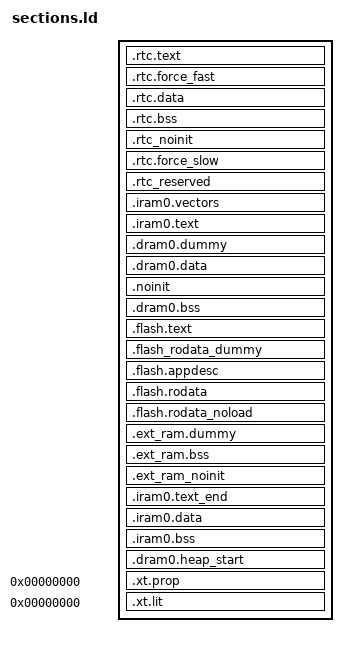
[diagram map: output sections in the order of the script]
/* Automatically generated file; DO NOT EDIT */
/* Espressif IoT Development Framework Linker Script */
/* Generated from: E:\esp\v5.1.6\esp-idf\components\esp_system\ld\esp32s3\sections.ld.in */

/*
 * SPDX-FileCopyrightText: 2021 Espressif Systems (Shanghai) CO LTD
 *
 * SPDX-License-Identifier: Apache-2.0
 */

/* Default entry point */
ENTRY(call_start_cpu0);

_diram_i_start = 0x40378000;

SECTIONS
{
  /**
   * RTC fast memory holds RTC wake stub code,
   * including from any source file named rtc_wake_stub*.c
   */
  .rtc.text :
  {
    . = ALIGN(4);
    _rtc_fast_start = ABSOLUTE(.);
    _rtc_text_start = ABSOLUTE(.);
    *(.rtc.entry.text)

    *(.rtc.literal .rtc.text .rtc.text.*)

    *rtc_wake_stub*.*(.literal .text .literal.* .text.*)
    *(.rtc_text_end_test)

    /* 16B padding for possible CPU prefetch and 4B alignment for PMS split lines */
    . += _esp_memprot_prefetch_pad_size;
    . = ALIGN(4);

    _rtc_text_end = ABSOLUTE(.);
  } > rtc_iram_seg

  /**
   * This section located in RTC FAST Memory area.
   * It holds data marked with RTC_FAST_ATTR attribute.
   * See the file "esp_attr.h" for more information.
   */
  .rtc.force_fast :
  {
    . = ALIGN(4);
    _rtc_force_fast_start = ABSOLUTE(.);

    _coredump_rtc_fast_start = ABSOLUTE(.);
    *(.rtc.fast.coredump .rtc.fast.coredump.*)
    _coredump_rtc_fast_end = ABSOLUTE(.);

    *(.rtc.force_fast .rtc.force_fast.*)
    . = ALIGN(4) ;
    _rtc_force_fast_end = ABSOLUTE(.);
  } > rtc_data_seg

  /**
   * RTC data section holds RTC wake stub
   * data/rodata, including from any source file
   * named rtc_wake_stub*.c and the data marked with
   * RTC_DATA_ATTR, RTC_RODATA_ATTR attributes.
   * The memory location of the data is dependent on
   * CONFIG_ESP32S3_RTCDATA_IN_FAST_MEM option.
   */
  .rtc.data :
  {
    _rtc_data_start = ABSOLUTE(.);

    _coredump_rtc_start = ABSOLUTE(.);
    *(.rtc.coredump .rtc.coredump.*)
    _coredump_rtc_end = ABSOLUTE(.);
    *(.rtc.data .rtc.data.*)
    *(.rtc.rodata .rtc.rodata.*)

    *rtc_wake_stub*.*(.data .rodata .data.* .rodata.*)
    _rtc_data_end = ABSOLUTE(.);
  } > rtc_data_location

  /* RTC bss, from any source file named rtc_wake_stub*.c */
  .rtc.bss (NOLOAD) :
  {
    _rtc_bss_start = ABSOLUTE(.);
    *rtc_wake_stub*.*(.bss .bss.*)
    *rtc_wake_stub*.*(COMMON)

    *(.rtc.bss)

    _rtc_bss_end = ABSOLUTE(.);
  } > rtc_data_location

  /**
   * This section holds data that should not be initialized at power up
   * and will be retained during deep sleep.
   * User data marked with RTC_NOINIT_ATTR will be placed
   * into this section. See the file "esp_attr.h" for more information.
	 * The memory location of the data is dependent on CONFIG_ESP32S3_RTCDATA_IN_FAST_MEM option.
   */
  .rtc_noinit (NOLOAD):
  {
    . = ALIGN(4);
    _rtc_noinit_start = ABSOLUTE(.);
    *(.rtc_noinit .rtc_noinit.*)
    . = ALIGN(4) ;
    _rtc_noinit_end = ABSOLUTE(.);
  } > rtc_data_location

  /**
   * This section located in RTC SLOW Memory area.
   * It holds data marked with RTC_SLOW_ATTR attribute.
   * See the file "esp_attr.h" for more information.
   */
  .rtc.force_slow :
  {
    . = ALIGN(4);
    _rtc_force_slow_start = ABSOLUTE(.);
    *(.rtc.force_slow .rtc.force_slow.*)
    . = ALIGN(4) ;
    _rtc_force_slow_end = ABSOLUTE(.);
  } > rtc_slow_seg

  /**
   * This section holds RTC data that should have fixed addresses.
   * The data are not initialized at power-up and are retained during deep sleep.
   */
  .rtc_reserved (NOLOAD):
  {
    . = ALIGN(4);
    _rtc_reserved_start = ABSOLUTE(.);
    /* New data can only be added here to ensure existing data are not moved.
       Because data have adhered to the end of the segment and code is relied on it.
       >> put new data here << */

    *(.rtc_timer_data_in_rtc_mem .rtc_timer_data_in_rtc_mem.*)
    KEEP(*(.bootloader_data_rtc_mem .bootloader_data_rtc_mem.*))
    _rtc_reserved_end = ABSOLUTE(.);
  } > rtc_reserved_seg

  _rtc_reserved_length = _rtc_reserved_end - _rtc_reserved_start;
  ASSERT((_rtc_reserved_length <= LENGTH(rtc_reserved_seg)),
          "RTC reserved segment data does not fit.")

  /* Get size of rtc slow data based on rtc_data_location alias */
  _rtc_slow_length = (ORIGIN(rtc_slow_seg) == ORIGIN(rtc_data_location))
                        ? (_rtc_force_slow_end - _rtc_data_start)
                        : (_rtc_force_slow_end - _rtc_force_slow_start);

  _rtc_fast_length = (ORIGIN(rtc_slow_seg) == ORIGIN(rtc_data_location))
                        ? (_rtc_force_fast_end - _rtc_fast_start)
                        : (_rtc_noinit_end - _rtc_fast_start);

  ASSERT((_rtc_slow_length <= LENGTH(rtc_slow_seg)),
          "RTC_SLOW segment data does not fit.")

  ASSERT((_rtc_fast_length <= LENGTH(rtc_data_seg)),
          "RTC_FAST segment data does not fit.")

  /* Send .iram0 code to iram */
  .iram0.vectors :
  {
    _iram_start = ABSOLUTE(.);
    /* Vectors go to IRAM */
    _vector_table = ABSOLUTE(.);
    . = 0x0;
    KEEP(*(.WindowVectors.text));
    . = 0x180;
    KEEP(*(.Level2InterruptVector.text));
    . = 0x1c0;
    KEEP(*(.Level3InterruptVector.text));
    . = 0x200;
    KEEP(*(.Level4InterruptVector.text));
    . = 0x240;
    KEEP(*(.Level5InterruptVector.text));
    . = 0x280;
    KEEP(*(.DebugExceptionVector.text));
    . = 0x2c0;
    KEEP(*(.NMIExceptionVector.text));
    . = 0x300;
    KEEP(*(.KernelExceptionVector.text));
    . = 0x340;
    KEEP(*(.UserExceptionVector.text));
    . = 0x3C0;
    KEEP(*(.DoubleExceptionVector.text));
    . = 0x400;
    _invalid_pc_placeholder = ABSOLUTE(.);
    *(.*Vector.literal)

    *(.UserEnter.literal);
    *(.UserEnter.text);
    . = ALIGN (16);
    *(.entry.text)
    *(.init.literal)
    *(.init)
    _init_end = ABSOLUTE(.);
  } > iram0_0_seg

  .iram0.text :
  {
    /* Code marked as running out of IRAM */
    _iram_text_start = ABSOLUTE(.);

    *(.iram1 .iram1.*)
    *libapp_trace.a:app_trace.*(.literal .literal.* .text .text.*)
    *libapp_trace.a:app_trace_util.*(.literal .literal.* .text .text.*)
    *libapp_trace.a:port_uart.*(.literal .literal.* .text .text.*)
    *libdriver.a:gptimer.*(.literal.gptimer_default_isr .text.gptimer_default_isr)
    *libesp_event.a:default_event_loop.*(.literal.esp_event_isr_post .text.esp_event_isr_post)
    *libesp_event.a:esp_event.*(.literal.esp_event_isr_post_to .text.esp_event_isr_post_to)
    *libesp_hw_support.a:cpu.*(.literal.esp_cpu_compare_and_set .text.esp_cpu_compare_and_set)
    *libesp_hw_support.a:cpu.*(.literal.esp_cpu_reset .text.esp_cpu_reset)
    *libesp_hw_support.a:cpu.*(.literal.esp_cpu_stall .text.esp_cpu_stall)
    *libesp_hw_support.a:cpu.*(.literal.esp_cpu_unstall .text.esp_cpu_unstall)
    *libesp_hw_support.a:cpu.*(.literal.esp_cpu_wait_for_intr .text.esp_cpu_wait_for_intr)
    *libesp_hw_support.a:esp_gpio_reserve.*(.literal.esp_gpio_is_pin_reserved .text.esp_gpio_is_pin_reserved)
    *libesp_hw_support.a:esp_gpio_reserve.*(.literal.esp_gpio_reserve_pins .text.esp_gpio_reserve_pins)
    *libesp_hw_support.a:esp_memory_utils.*(.literal .literal.* .text .text.*)
    *libesp_hw_support.a:mspi_timing_config.*(.literal .literal.* .text .text.*)
    *libesp_hw_support.a:mspi_timing_tuning.*(.literal .literal.* .text .text.*)
    *libesp_hw_support.a:rtc_clk.*(.literal .literal.* .text .text.*)
    *libesp_hw_support.a:rtc_sleep.*(.literal .literal.* .text .text.*)
    *libesp_hw_support.a:rtc_time.*(.literal .literal.* .text .text.*)
    *libesp_hw_support.a:sar_periph_ctrl.*(.literal.sar_periph_ctrl_power_enable .text.sar_periph_ctrl_power_enable)
    *libesp_hw_support.a:sleep_console.*(.literal .literal.* .text .text.*)
    *libesp_hw_support.a:systimer.*(.literal .literal.* .text .text.*)
    *libesp_mm.a:esp_cache.*(.literal .literal.* .text .text.*)
    *libesp_psram.a:esp_psram_impl_octal.*(.literal .literal.* .text .text.*)
    *libesp_psram.a:mmu_psram_flash.*(.literal .literal.* .text .text.*)
    *libesp_ringbuf.a:(EXCLUDE_FILE(*libesp_ringbuf.a:ringbuf.*) .literal EXCLUDE_FILE(*libesp_ringbuf.a:ringbuf.*) .literal.* EXCLUDE_FILE(*libesp_ringbuf.a:ringbuf.*) .text EXCLUDE_FILE(*libesp_ringbuf.a:ringbuf.*) .text.*)
    *libesp_ringbuf.a:ringbuf.*(.literal.prvAcquireItemNoSplit .literal.prvCheckItemFitsByteBuffer .literal.prvCheckItemFitsDefault .literal.prvCopyItemAllowSplit .literal.prvCopyItemByteBuf .literal.prvCopyItemNoSplit .literal.prvGetItemByteBuf .literal.prvGetItemDefault .literal.prvReceiveGenericFromISR .literal.prvReturnItemByteBuf .literal.prvReturnItemDefault .literal.prvSendItemDoneNoSplit .literal.vRingbufferReturnItemFromISR .literal.xRingbufferReceiveFromISR .literal.xRingbufferReceiveSplitFromISR .literal.xRingbufferReceiveUpToFromISR .literal.xRingbufferSendFromISR .text .text.prvAcquireItemNoSplit .text.prvCheckItemAvail .text.prvCheckItemFitsByteBuffer .text.prvCheckItemFitsDefault .text.prvCopyItemAllowSplit .text.prvCopyItemByteBuf .text.prvCopyItemNoSplit .text.prvGetItemByteBuf .text.prvGetItemDefault .text.prvReceiveGenericFromISR .text.prvReturnItemByteBuf .text.prvReturnItemDefault .text.prvSendItemDoneNoSplit .text.vRingbufferReturnItemFromISR .text.xRingbufferReceiveFromISR .text.xRingbufferReceiveSplitFromISR .text.xRingbufferReceiveUpToFromISR .text.xRingbufferSendFromISR)
    *libesp_rom.a:esp_rom_cache_esp32s2_esp32s3.*(.literal .literal.* .text .text.*)
    *libesp_rom.a:esp_rom_cache_writeback_esp32s3.*(.literal .literal.* .text .text.*)
    *libesp_rom.a:esp_rom_spiflash.*(.literal .literal.* .text .text.*)
    *libesp_rom.a:esp_rom_systimer.*(.literal .literal.* .text .text.*)
    *libesp_rom.a:esp_rom_wdt.*(.literal .literal.* .text .text.*)
    *libesp_system.a:esp_err.*(.literal .literal.* .text .text.*)
    *libesp_system.a:esp_system_chip.*(.literal.esp_system_abort .text.esp_system_abort)
    *libesp_system.a:ubsan.*(.literal .literal.* .text .text.*)
    *libfreertos.a:(EXCLUDE_FILE(*libfreertos.a:app_startup.* *libfreertos.a:event_groups.* *libfreertos.a:heap_idf.* *libfreertos.a:idf_additions.* *libfreertos.a:list.* *libfreertos.a:port.* *libfreertos.a:port_common.* *libfreertos.a:queue.* *libfreertos.a:stream_buffer.* *libfreertos.a:tasks.* *libfreertos.a:timers.*) .literal EXCLUDE_FILE(*libfreertos.a:app_startup.* *libfreertos.a:event_groups.* *libfreertos.a:heap_idf.* *libfreertos.a:idf_additions.* *libfreertos.a:list.* *libfreertos.a:port.* *libfreertos.a:port_common.* *libfreertos.a:queue.* *libfreertos.a:stream_buffer.* *libfreertos.a:tasks.* *libfreertos.a:timers.*) .literal.* EXCLUDE_FILE(*libfreertos.a:app_startup.* *libfreertos.a:event_groups.* *libfreertos.a:heap_idf.* *libfreertos.a:idf_additions.* *libfreertos.a:list.* *libfreertos.a:port.* *libfreertos.a:port_common.* *libfreertos.a:queue.* *libfreertos.a:stream_buffer.* *libfreertos.a:tasks.* *libfreertos.a:timers.*) .text EXCLUDE_FILE(*libfreertos.a:app_startup.* *libfreertos.a:event_groups.* *libfreertos.a:heap_idf.* *libfreertos.a:idf_additions.* *libfreertos.a:list.* *libfreertos.a:port.* *libfreertos.a:port_common.* *libfreertos.a:queue.* *libfreertos.a:stream_buffer.* *libfreertos.a:tasks.* *libfreertos.a:timers.*) .text.*)
    *libfreertos.a:event_groups.*(.literal.xEventGroupGetBitsFromISR .literal.xEventGroupGetStaticBuffer .text .text.xEventGroupGetBitsFromISR .text.xEventGroupGetStaticBuffer)
    *libfreertos.a:heap_idf.*(.text)
    *libfreertos.a:list.*(.text .text.uxListRemove .text.vListInsert .text.vListInsertEnd)
    *libfreertos.a:port.*(.literal.unlikely.vPortEndScheduler .literal.vApplicationStackOverflowHook .literal.vPortAssertIfInISR .literal.vPortExitCritical .literal.vPortExitCriticalCompliance .literal.vPortSetStackWatchpoint .literal.vPortYieldOtherCore .literal.xPortEnterCriticalTimeout .literal.xPortEnterCriticalTimeoutCompliance .literal.xPortInIsrContext .text .text.unlikely.vPortEndScheduler .text.vApplicationStackOverflowHook .text.vPortAssertIfInISR .text.vPortExitCritical .text.vPortExitCriticalCompliance .text.vPortSetStackWatchpoint .text.vPortYieldOtherCore .text.xPortEnterCriticalTimeout .text.xPortEnterCriticalTimeoutCompliance .text.xPortInIsrContext)
    *libfreertos.a:port_common.*(.text)
    *libfreertos.a:queue.*(.literal.prvCopyDataFromQueue .literal.prvCopyDataToQueue .literal.prvNotifyQueueSetContainer .literal.uxQueueMessagesWaitingFromISR .literal.xQueueGenericGetStaticBuffers .literal.xQueueGenericSendFromISR .literal.xQueueGetMutexHolderFromISR .literal.xQueueGiveFromISR .literal.xQueueIsQueueEmptyFromISR .literal.xQueueIsQueueFullFromISR .literal.xQueuePeekFromISR .literal.xQueueReceiveFromISR .literal.xQueueSelectFromSetFromISR .text .text.prvCopyDataFromQueue .text.prvCopyDataToQueue .text.prvNotifyQueueSetContainer .text.uxQueueMessagesWaitingFromISR .text.xQueueGenericGetStaticBuffers .text.xQueueGenericSendFromISR .text.xQueueGetMutexHolderFromISR .text.xQueueGiveFromISR .text.xQueueIsQueueEmptyFromISR .text.xQueueIsQueueFullFromISR .text.xQueuePeekFromISR .text.xQueueReceiveFromISR .text.xQueueSelectFromSetFromISR)
    *libfreertos.a:stream_buffer.*(.literal.xStreamBufferGetStaticBuffers .literal.xStreamBufferReceiveCompletedFromISR .literal.xStreamBufferReceiveFromISR .literal.xStreamBufferSendCompletedFromISR .literal.xStreamBufferSendFromISR .literal.xStreamBufferSpacesAvailable .text .text.prvBytesInBuffer .text.xStreamBufferGetStaticBuffers .text.xStreamBufferReceiveCompletedFromISR .text.xStreamBufferReceiveFromISR .text.xStreamBufferSendCompletedFromISR .text.xStreamBufferSendFromISR .text.xStreamBufferSpacesAvailable)
    *libfreertos.a:tasks.*(.literal.__getreent .literal.prvCheckForYieldUsingPrioritySMP .literal.prvInitialiseNewTask$constprop$0 .literal.prvResetNextTaskUnblockTime .literal.prvTaskIsTaskSuspended .literal.pxGetNextTaskList .literal.pxTaskGetNext .literal.uxTaskGetSnapshotAll .literal.uxTaskPriorityGetFromISR .literal.vTaskGenericNotifyGiveFromISR .literal.vTaskGetSnapshot .literal.vTaskSwitchContext .literal.xTaskCatchUpTicks .literal.xTaskGenericNotifyFromISR .literal.xTaskGetSchedulerState .literal.xTaskGetStaticBuffers .literal.xTaskGetTickCount .literal.xTaskGetTickCountFromISR .literal.xTaskIncrementTick .literal.xTaskIncrementTickOtherCores .literal.xTaskRemoveFromEventList .literal.xTaskResumeFromISR .text .text.__getreent .text.prvCheckForYieldUsingPrioritySMP .text.prvInitialiseNewTask$constprop$0 .text.prvResetNextTaskUnblockTime .text.prvTaskIsTaskSuspended .text.pxGetNextTaskList .text.pxTaskGetNext .text.uxTaskGetSnapshotAll .text.uxTaskPriorityGetFromISR .text.vTaskGenericNotifyGiveFromISR .text.vTaskGetSnapshot .text.vTaskSwitchContext .text.xTaskCatchUpTicks .text.xTaskGenericNotifyFromISR .text.xTaskGetSchedulerState .text.xTaskGetStaticBuffers .text.xTaskGetTickCount .text.xTaskGetTickCountFromISR .text.xTaskIncrementTick .text.xTaskIncrementTickOtherCores .text.xTaskRemoveFromEventList .text.xTaskResumeFromISR .text.xTimerCreateTimerTask)
    *libfreertos.a:timers.*(.literal.xTimerGetStaticBuffer .literal.xTimerPendFunctionCallFromISR .text .text.xTimerGetStaticBuffer .text.xTimerPendFunctionCallFromISR)
    *libgcc.a:_divsf3.*(.literal .literal.* .text .text.*)
    *libgcc.a:lib2funcs.*(.literal .literal.* .text .text.*)
    *libgcov.a:(.literal .literal.* .text .text.*)
    *libhal.a:cache_hal.*(.literal .literal.* .text .text.*)
    *libhal.a:i2c_hal_iram.*(.literal .literal.* .text .text.*)
    *libhal.a:ledc_hal_iram.*(.literal .literal.* .text .text.*)
    *libhal.a:mmu_hal.*(.literal .literal.* .text .text.*)
    *libhal.a:spi_flash_encrypt_hal_iram.*(.literal .literal.* .text .text.*)
    *libhal.a:spi_flash_hal_gpspi.*(.literal .literal.* .text .text.*)
    *libhal.a:spi_flash_hal_iram.*(.literal .literal.* .text .text.*)
    *libhal.a:systimer_hal.*(.literal .literal.* .text .text.*)
    *libhal.a:timer_hal.*(.literal.timer_hal_capture_and_get_counter_value .text.timer_hal_capture_and_get_counter_value)
    *libheap.a:multi_heap.*(.literal.assert_valid_block .text.assert_valid_block)
    *libheap.a:multi_heap.*(.literal.multi_heap_aligned_alloc_impl .text.multi_heap_aligned_alloc_impl)
    *libheap.a:multi_heap.*(.literal.multi_heap_aligned_alloc_impl_offs .text.multi_heap_aligned_alloc_impl_offs)
    *libheap.a:multi_heap.*(.literal.multi_heap_free_impl .text.multi_heap_free_impl)
    *libheap.a:multi_heap.*(.literal.multi_heap_get_allocated_size_impl .text.multi_heap_get_allocated_size_impl)
    *libheap.a:multi_heap.*(.literal.multi_heap_get_block_address_impl .text.multi_heap_get_block_address_impl)
    *libheap.a:multi_heap.*(.literal.multi_heap_get_first_block .text.multi_heap_get_first_block)
    *libheap.a:multi_heap.*(.literal.multi_heap_get_next_block .text.multi_heap_get_next_block)
    *libheap.a:multi_heap.*(.literal.multi_heap_internal_lock .text.multi_heap_internal_lock)
    *libheap.a:multi_heap.*(.literal.multi_heap_internal_unlock .text.multi_heap_internal_unlock)
    *libheap.a:multi_heap.*(.literal.multi_heap_is_free .text.multi_heap_is_free)
    *libheap.a:multi_heap.*(.literal.multi_heap_malloc_impl .text.multi_heap_malloc_impl)
    *libheap.a:multi_heap.*(.literal.multi_heap_realloc_impl .text.multi_heap_realloc_impl)
    *libheap.a:multi_heap.*(.literal.multi_heap_set_lock .text.multi_heap_set_lock)
    *libheap.a:tlsf.*(.literal.tlsf_align_size .text.tlsf_align_size)
    *libheap.a:tlsf.*(.literal.tlsf_alloc_overhead .text.tlsf_alloc_overhead)
    *libheap.a:tlsf.*(.literal.tlsf_block_size .text.tlsf_block_size)
    *libheap.a:tlsf.*(.literal.tlsf_block_size_max .text.tlsf_block_size_max)
    *libheap.a:tlsf.*(.literal.tlsf_block_size_min .text.tlsf_block_size_min)
    *libheap.a:tlsf.*(.literal.tlsf_free .text.tlsf_free)
    *libheap.a:tlsf.*(.literal.tlsf_get_pool .text.tlsf_get_pool)
    *libheap.a:tlsf.*(.literal.tlsf_malloc .text.tlsf_malloc)
    *libheap.a:tlsf.*(.literal.tlsf_memalign .text.tlsf_memalign)
    *libheap.a:tlsf.*(.literal.tlsf_memalign_offs .text.tlsf_memalign_offs)
    *libheap.a:tlsf.*(.literal.tlsf_realloc .text.tlsf_realloc)
    *libheap.a:tlsf.*(.literal.tlsf_size .text.tlsf_size)
    *liblog.a:log.*(.literal.esp_log_write .text.esp_log_write)
    *liblog.a:log_freertos.*(.literal.esp_log_early_timestamp .text.esp_log_early_timestamp)
    *liblog.a:log_freertos.*(.literal.esp_log_impl_lock .text.esp_log_impl_lock)
    *liblog.a:log_freertos.*(.literal.esp_log_impl_lock_timeout .text.esp_log_impl_lock_timeout)
    *liblog.a:log_freertos.*(.literal.esp_log_impl_unlock .text.esp_log_impl_unlock)
    *liblog.a:log_freertos.*(.literal.esp_log_timestamp .text.esp_log_timestamp)
    *libnewlib.a:abort.*(.literal .literal.* .text .text.*)
    *libnewlib.a:assert.*(.literal .literal.* .text .text.*)
    *libnewlib.a:heap.*(.literal .literal.* .text .text.*)
    *libnewlib.a:stdatomic.*(.literal .literal.* .text .text.*)
    *librtc.a:(.literal .literal.* .text .text.*)
    *libsoc.a:lldesc.*(.literal .literal.* .text .text.*)
    *libspi_flash.a:flash_brownout_hook.*(.literal .literal.* .text .text.*)
    *libspi_flash.a:memspi_host_driver.*(.literal .literal.* .text .text.*)
    *libspi_flash.a:spi_flash_chip_boya.*(.literal .literal.* .text .text.*)
    *libspi_flash.a:spi_flash_chip_gd.*(.literal .literal.* .text .text.*)
    *libspi_flash.a:spi_flash_chip_generic.*(.literal .literal.* .text .text.*)
    *libspi_flash.a:spi_flash_chip_issi.*(.literal .literal.* .text .text.*)
    *libspi_flash.a:spi_flash_chip_mxic.*(.literal .literal.* .text .text.*)
    *libspi_flash.a:spi_flash_chip_mxic_opi.*(.literal .literal.* .text .text.*)
    *libspi_flash.a:spi_flash_chip_th.*(.literal .literal.* .text .text.*)
    *libspi_flash.a:spi_flash_chip_winbond.*(.literal .literal.* .text .text.*)
    *libspi_flash.a:spi_flash_hpm_enable.*(.literal .literal.* .text .text.*)
    *libspi_flash.a:spi_flash_oct_flash_init.*(.literal .literal.* .text .text.*)
    *libspi_flash.a:spi_flash_wrap.*(.literal .literal.* .text .text.*)
    *libxt_hal.a:(.literal .literal.* .text .text.*)
    *libxtensa.a:eri.*(.literal .literal.* .text .text.*)
    *libxtensa.a:xtensa_intr_asm.*(.literal .literal.* .text .text.*)

  } > iram0_0_seg

  /**
   * This section is required to skip .iram0.text area because iram0_0_seg and
   * dram0_0_seg reflect the same address space on different buses.
   */
  .dram0.dummy (NOLOAD):
  {
    . = ORIGIN(dram0_0_seg) + MAX(_iram_end - _diram_i_start, 0);
  } > dram0_0_seg

  .dram0.data :
  {
    _data_start = ABSOLUTE(.);
    *(.gnu.linkonce.d.*)
    *(.data1)
    *(.sdata)
    *(.sdata.*)
    *(.gnu.linkonce.s.*)
    *(.gnu.linkonce.s2.*)
    *(.jcr)

    *(.data .data.*)
    *(.dram1 .dram1.*)
    _coredump_dram_start = ABSOLUTE(.);
    *(.dram2.coredump .dram2.coredump.*)
    _coredump_dram_end = ABSOLUTE(.);
    *libapp_trace.a:app_trace.*(.rodata .rodata.* .sdata2 .sdata2.* .srodata .srodata.*)
    *libapp_trace.a:app_trace_util.*(.rodata .rodata.* .sdata2 .sdata2.* .srodata .srodata.*)
    *libapp_trace.a:port_uart.*(.rodata .rodata.* .sdata2 .sdata2.* .srodata .srodata.*)
    *libesp_hw_support.a:esp_memory_utils.*(.rodata .rodata.* .sdata2 .sdata2.* .srodata .srodata.*)
    *libesp_hw_support.a:mspi_timing_config.*(.rodata .rodata.* .sdata2 .sdata2.* .srodata .srodata.*)
    *libesp_hw_support.a:mspi_timing_tuning.*(.rodata .rodata.* .sdata2 .sdata2.* .srodata .srodata.*)
    *libesp_hw_support.a:rtc_clk.*(.rodata .rodata.* .sdata2 .sdata2.* .srodata .srodata.*)
    *libesp_hw_support.a:sleep_console.*(.rodata .rodata.* .sdata2 .sdata2.* .srodata .srodata.*)
    *libesp_hw_support.a:systimer.*(.rodata .rodata.* .sdata2 .sdata2.* .srodata .srodata.*)
    *libesp_mm.a:esp_cache.*(.rodata .rodata.* .sdata2 .sdata2.* .srodata .srodata.*)
    *libesp_psram.a:esp_psram_impl_octal.*(.rodata .rodata.* .sdata2 .sdata2.* .srodata .srodata.*)
    *libesp_psram.a:mmu_psram_flash.*(.rodata .rodata.* .sdata2 .sdata2.* .srodata .srodata.*)
    *libesp_rom.a:esp_rom_cache_esp32s2_esp32s3.*(.rodata .rodata.* .sdata2 .sdata2.* .srodata .srodata.*)
    *libesp_rom.a:esp_rom_cache_writeback_esp32s3.*(.rodata .rodata.* .sdata2 .sdata2.* .srodata .srodata.*)
    *libesp_rom.a:esp_rom_spiflash.*(.rodata .rodata.* .sdata2 .sdata2.* .srodata .srodata.*)
    *libesp_rom.a:esp_rom_systimer.*(.rodata .rodata.* .sdata2 .sdata2.* .srodata .srodata.*)
    *libesp_rom.a:esp_rom_wdt.*(.rodata .rodata.* .sdata2 .sdata2.* .srodata .srodata.*)
    *libesp_system.a:esp_err.*(.rodata .rodata.* .sdata2 .sdata2.* .srodata .srodata.*)
    *libesp_system.a:ubsan.*(.rodata .rodata.* .sdata2 .sdata2.* .srodata .srodata.*)
    *libfreertos.a:FreeRTOS-openocd.*(.rodata .rodata.* .sdata2 .sdata2.* .srodata .srodata.*)
    *libgcc.a:_divsf3.*(.rodata .rodata.* .sdata2 .sdata2.* .srodata .srodata.*)
    *libgcov.a:(.rodata .rodata.* .sdata2 .sdata2.* .srodata .srodata.*)
    *libhal.a:cache_hal.*(.rodata .rodata.* .sdata2 .sdata2.* .srodata .srodata.*)
    *libhal.a:i2c_hal_iram.*(.rodata .rodata.* .sdata2 .sdata2.* .srodata .srodata.*)
    *libhal.a:ledc_hal_iram.*(.rodata .rodata.* .sdata2 .sdata2.* .srodata .srodata.*)
    *libhal.a:mmu_hal.*(.rodata .rodata.* .sdata2 .sdata2.* .srodata .srodata.*)
    *libhal.a:spi_flash_encrypt_hal_iram.*(.rodata .rodata.* .sdata2 .sdata2.* .srodata .srodata.*)
    *libhal.a:spi_flash_hal_gpspi.*(.rodata .rodata.* .sdata2 .sdata2.* .srodata .srodata.*)
    *libhal.a:spi_flash_hal_iram.*(.rodata .rodata.* .sdata2 .sdata2.* .srodata .srodata.*)
    *libhal.a:systimer_hal.*(.rodata .rodata.* .sdata2 .sdata2.* .srodata .srodata.*)
    *libnewlib.a:abort.*(.rodata .rodata.* .sdata2 .sdata2.* .srodata .srodata.*)
    *libnewlib.a:assert.*(.rodata .rodata.* .sdata2 .sdata2.* .srodata .srodata.*)
    *libnewlib.a:heap.*(.rodata .rodata.* .sdata2 .sdata2.* .srodata .srodata.*)
    *libnewlib.a:stdatomic.*(.rodata .rodata.* .sdata2 .sdata2.* .srodata .srodata.*)
    *libphy.a:(.rodata .rodata.* .sdata2 .sdata2.* .srodata .srodata.*)
    *libsoc.a:lldesc.*(.rodata .rodata.* .sdata2 .sdata2.* .srodata .srodata.*)
    *libspi_flash.a:flash_brownout_hook.*(.rodata .rodata.* .sdata2 .sdata2.* .srodata .srodata.*)
    *libspi_flash.a:memspi_host_driver.*(.rodata .rodata.* .sdata2 .sdata2.* .srodata .srodata.*)
    *libspi_flash.a:spi_flash_chip_boya.*(.rodata .rodata.* .sdata2 .sdata2.* .srodata .srodata.*)
    *libspi_flash.a:spi_flash_chip_gd.*(.rodata .rodata.* .sdata2 .sdata2.* .srodata .srodata.*)
    *libspi_flash.a:spi_flash_chip_generic.*(.rodata .rodata.* .sdata2 .sdata2.* .srodata .srodata.*)
    *libspi_flash.a:spi_flash_chip_issi.*(.rodata .rodata.* .sdata2 .sdata2.* .srodata .srodata.*)
    *libspi_flash.a:spi_flash_chip_mxic.*(.rodata .rodata.* .sdata2 .sdata2.* .srodata .srodata.*)
    *libspi_flash.a:spi_flash_chip_mxic_opi.*(.rodata .rodata.* .sdata2 .sdata2.* .srodata .srodata.*)
    *libspi_flash.a:spi_flash_chip_th.*(.rodata .rodata.* .sdata2 .sdata2.* .srodata .srodata.*)
    *libspi_flash.a:spi_flash_chip_winbond.*(.rodata .rodata.* .sdata2 .sdata2.* .srodata .srodata.*)
    *libspi_flash.a:spi_flash_hpm_enable.*(.rodata .rodata.* .sdata2 .sdata2.* .srodata .srodata.*)
    *libspi_flash.a:spi_flash_oct_flash_init.*(.rodata .rodata.* .sdata2 .sdata2.* .srodata .srodata.*)
    *libspi_flash.a:spi_flash_wrap.*(.rodata .rodata.* .sdata2 .sdata2.* .srodata .srodata.*)

    _data_end = ABSOLUTE(.);
    . = ALIGN(4);
  } > dram0_0_seg

  /**
   * This section holds data that should not be initialized at power up.
   * The section located in Internal SRAM memory region. The macro _NOINIT
   * can be used as attribute to place data into this section.
   * See the "esp_attr.h" file for more information.
   */
  .noinit (NOLOAD):
  {
    . = ALIGN(4);
    _noinit_start = ABSOLUTE(.);
    *(.noinit .noinit.*)
    . = ALIGN(4) ;
    _noinit_end = ABSOLUTE(.);
  } > dram0_0_seg

  /* Shared RAM */
  .dram0.bss (NOLOAD) :
  {
    . = ALIGN (8);
    _bss_start = ABSOLUTE(.);

    *(.bss .bss.*)
    *(.dynbss .dynsbss .gnu.linkonce.b .gnu.linkonce.b.* .gnu.linkonce.sb .gnu.linkonce.sb.* .gnu.linkonce.sb2 .gnu.linkonce.sb2.* .sbss .sbss.* .sbss2 .sbss2.* .scommon .share.mem)
    *(.ext_ram.bss .ext_ram.bss.*)
    *(COMMON)

    *(.dynsbss)
    *(.sbss)
    *(.sbss.*)
    *(.gnu.linkonce.sb.*)
    *(.scommon)
    *(.sbss2)
    *(.sbss2.*)
    *(.gnu.linkonce.sb2.*)
    *(.dynbss)
    *(.share.mem)
    *(.gnu.linkonce.b.*)

    . = ALIGN (8);
    _bss_end = ABSOLUTE(.);
  } > dram0_0_seg

  ASSERT(((_bss_end - ORIGIN(dram0_0_seg)) <= LENGTH(dram0_0_seg)), "DRAM segment data does not fit.")

  .flash.text :
  {
    _stext = .;
    _instruction_reserved_start = ABSOLUTE(.);  /* This is a symbol marking the flash.text start, this can be used for mmu driver to maintain virtual address */
    _text_start = ABSOLUTE(.);

    *(EXCLUDE_FILE(*libesp_ringbuf.a *libfreertos.a *libgcov.a *librtc.a *libxt_hal.a *libapp_trace.a:app_trace.* *libapp_trace.a:app_trace_util.* *libapp_trace.a:port_uart.* *libdriver.a:gptimer.* *libesp_event.a:default_event_loop.* *libesp_event.a:esp_event.* *libesp_hw_support.a:cpu.* *libesp_hw_support.a:esp_gpio_reserve.* *libesp_hw_support.a:esp_memory_utils.* *libesp_hw_support.a:mspi_timing_config.* *libesp_hw_support.a:mspi_timing_tuning.* *libesp_hw_support.a:rtc_clk.* *libesp_hw_support.a:rtc_sleep.* *libesp_hw_support.a:rtc_time.* *libesp_hw_support.a:sar_periph_ctrl.* *libesp_hw_support.a:sleep_console.* *libesp_hw_support.a:systimer.* *libesp_mm.a:esp_cache.* *libesp_psram.a:esp_psram_impl_octal.* *libesp_psram.a:mmu_psram_flash.* *libesp_rom.a:esp_rom_cache_esp32s2_esp32s3.* *libesp_rom.a:esp_rom_cache_writeback_esp32s3.* *libesp_rom.a:esp_rom_spiflash.* *libesp_rom.a:esp_rom_systimer.* *libesp_rom.a:esp_rom_wdt.* *libesp_system.a:esp_err.* *libesp_system.a:esp_system_chip.* *libesp_system.a:ubsan.* *libgcc.a:_divsf3.* *libgcc.a:lib2funcs.* *libhal.a:cache_hal.* *libhal.a:i2c_hal_iram.* *libhal.a:ledc_hal_iram.* *libhal.a:mmu_hal.* *libhal.a:spi_flash_encrypt_hal_iram.* *libhal.a:spi_flash_hal_gpspi.* *libhal.a:spi_flash_hal_iram.* *libhal.a:systimer_hal.* *libhal.a:timer_hal.* *libheap.a:multi_heap.* *libheap.a:tlsf.* *liblog.a:log.* *liblog.a:log_freertos.* *libnewlib.a:abort.* *libnewlib.a:assert.* *libnewlib.a:heap.* *libnewlib.a:stdatomic.* *libsoc.a:lldesc.* *libspi_flash.a:flash_brownout_hook.* *libspi_flash.a:memspi_host_driver.* *libspi_flash.a:spi_flash_chip_boya.* *libspi_flash.a:spi_flash_chip_gd.* *libspi_flash.a:spi_flash_chip_generic.* *libspi_flash.a:spi_flash_chip_issi.* *libspi_flash.a:spi_flash_chip_mxic.* *libspi_flash.a:spi_flash_chip_mxic_opi.* *libspi_flash.a:spi_flash_chip_th.* *libspi_flash.a:spi_flash_chip_winbond.* *libspi_flash.a:spi_flash_hpm_enable.* *libspi_flash.a:spi_flash_oct_flash_init.* *libspi_flash.a:spi_flash_wrap.* *libxtensa.a:eri.* *libxtensa.a:xtensa_intr_asm.*) .literal EXCLUDE_FILE(*libesp_ringbuf.a *libfreertos.a *libgcov.a *librtc.a *libxt_hal.a *libapp_trace.a:app_trace.* *libapp_trace.a:app_trace_util.* *libapp_trace.a:port_uart.* *libdriver.a:gptimer.* *libesp_event.a:default_event_loop.* *libesp_event.a:esp_event.* *libesp_hw_support.a:cpu.* *libesp_hw_support.a:esp_gpio_reserve.* *libesp_hw_support.a:esp_memory_utils.* *libesp_hw_support.a:mspi_timing_config.* *libesp_hw_support.a:mspi_timing_tuning.* *libesp_hw_support.a:rtc_clk.* *libesp_hw_support.a:rtc_sleep.* *libesp_hw_support.a:rtc_time.* *libesp_hw_support.a:sar_periph_ctrl.* *libesp_hw_support.a:sleep_console.* *libesp_hw_support.a:systimer.* *libesp_mm.a:esp_cache.* *libesp_psram.a:esp_psram_impl_octal.* *libesp_psram.a:mmu_psram_flash.* *libesp_rom.a:esp_rom_cache_esp32s2_esp32s3.* *libesp_rom.a:esp_rom_cache_writeback_esp32s3.* *libesp_rom.a:esp_rom_spiflash.* *libesp_rom.a:esp_rom_systimer.* *libesp_rom.a:esp_rom_wdt.* *libesp_system.a:esp_err.* *libesp_system.a:esp_system_chip.* *libesp_system.a:ubsan.* *libgcc.a:_divsf3.* *libgcc.a:lib2funcs.* *libhal.a:cache_hal.* *libhal.a:i2c_hal_iram.* *libhal.a:ledc_hal_iram.* *libhal.a:mmu_hal.* *libhal.a:spi_flash_encrypt_hal_iram.* *libhal.a:spi_flash_hal_gpspi.* *libhal.a:spi_flash_hal_iram.* *libhal.a:systimer_hal.* *libhal.a:timer_hal.* *libheap.a:multi_heap.* *libheap.a:tlsf.* *liblog.a:log.* *liblog.a:log_freertos.* *libnewlib.a:abort.* *libnewlib.a:assert.* *libnewlib.a:heap.* *libnewlib.a:stdatomic.* *libsoc.a:lldesc.* *libspi_flash.a:flash_brownout_hook.* *libspi_flash.a:memspi_host_driver.* *libspi_flash.a:spi_flash_chip_boya.* *libspi_flash.a:spi_flash_chip_gd.* *libspi_flash.a:spi_flash_chip_generic.* *libspi_flash.a:spi_flash_chip_issi.* *libspi_flash.a:spi_flash_chip_mxic.* *libspi_flash.a:spi_flash_chip_mxic_opi.* *libspi_flash.a:spi_flash_chip_th.* *libspi_flash.a:spi_flash_chip_winbond.* *libspi_flash.a:spi_flash_hpm_enable.* *libspi_flash.a:spi_flash_oct_flash_init.* *libspi_flash.a:spi_flash_wrap.* *libxtensa.a:eri.* *libxtensa.a:xtensa_intr_asm.*) .literal.* EXCLUDE_FILE(*libesp_ringbuf.a *libfreertos.a *libgcov.a *librtc.a *libxt_hal.a *libapp_trace.a:app_trace.* *libapp_trace.a:app_trace_util.* *libapp_trace.a:port_uart.* *libdriver.a:gptimer.* *libesp_event.a:default_event_loop.* *libesp_event.a:esp_event.* *libesp_hw_support.a:cpu.* *libesp_hw_support.a:esp_gpio_reserve.* *libesp_hw_support.a:esp_memory_utils.* *libesp_hw_support.a:mspi_timing_config.* *libesp_hw_support.a:mspi_timing_tuning.* *libesp_hw_support.a:rtc_clk.* *libesp_hw_support.a:rtc_sleep.* *libesp_hw_support.a:rtc_time.* *libesp_hw_support.a:sar_periph_ctrl.* *libesp_hw_support.a:sleep_console.* *libesp_hw_support.a:systimer.* *libesp_mm.a:esp_cache.* *libesp_psram.a:esp_psram_impl_octal.* *libesp_psram.a:mmu_psram_flash.* *libesp_rom.a:esp_rom_cache_esp32s2_esp32s3.* *libesp_rom.a:esp_rom_cache_writeback_esp32s3.* *libesp_rom.a:esp_rom_spiflash.* *libesp_rom.a:esp_rom_systimer.* *libesp_rom.a:esp_rom_wdt.* *libesp_system.a:esp_err.* *libesp_system.a:esp_system_chip.* *libesp_system.a:ubsan.* *libgcc.a:_divsf3.* *libgcc.a:lib2funcs.* *libhal.a:cache_hal.* *libhal.a:i2c_hal_iram.* *libhal.a:ledc_hal_iram.* *libhal.a:mmu_hal.* *libhal.a:spi_flash_encrypt_hal_iram.* *libhal.a:spi_flash_hal_gpspi.* *libhal.a:spi_flash_hal_iram.* *libhal.a:systimer_hal.* *libhal.a:timer_hal.* *libheap.a:multi_heap.* *libheap.a:tlsf.* *liblog.a:log.* *liblog.a:log_freertos.* *libnewlib.a:abort.* *libnewlib.a:assert.* *libnewlib.a:heap.* *libnewlib.a:stdatomic.* *libsoc.a:lldesc.* *libspi_flash.a:flash_brownout_hook.* *libspi_flash.a:memspi_host_driver.* *libspi_flash.a:spi_flash_chip_boya.* *libspi_flash.a:spi_flash_chip_gd.* *libspi_flash.a:spi_flash_chip_generic.* *libspi_flash.a:spi_flash_chip_issi.* *libspi_flash.a:spi_flash_chip_mxic.* *libspi_flash.a:spi_flash_chip_mxic_opi.* *libspi_flash.a:spi_flash_chip_th.* *libspi_flash.a:spi_flash_chip_winbond.* *libspi_flash.a:spi_flash_hpm_enable.* *libspi_flash.a:spi_flash_oct_flash_init.* *libspi_flash.a:spi_flash_wrap.* *libxtensa.a:eri.* *libxtensa.a:xtensa_intr_asm.*) .text EXCLUDE_FILE(*libesp_ringbuf.a *libfreertos.a *libgcov.a *librtc.a *libxt_hal.a *libapp_trace.a:app_trace.* *libapp_trace.a:app_trace_util.* *libapp_trace.a:port_uart.* *libdriver.a:gptimer.* *libesp_event.a:default_event_loop.* *libesp_event.a:esp_event.* *libesp_hw_support.a:cpu.* *libesp_hw_support.a:esp_gpio_reserve.* *libesp_hw_support.a:esp_memory_utils.* *libesp_hw_support.a:mspi_timing_config.* *libesp_hw_support.a:mspi_timing_tuning.* *libesp_hw_support.a:rtc_clk.* *libesp_hw_support.a:rtc_sleep.* *libesp_hw_support.a:rtc_time.* *libesp_hw_support.a:sar_periph_ctrl.* *libesp_hw_support.a:sleep_console.* *libesp_hw_support.a:systimer.* *libesp_mm.a:esp_cache.* *libesp_psram.a:esp_psram_impl_octal.* *libesp_psram.a:mmu_psram_flash.* *libesp_rom.a:esp_rom_cache_esp32s2_esp32s3.* *libesp_rom.a:esp_rom_cache_writeback_esp32s3.* *libesp_rom.a:esp_rom_spiflash.* *libesp_rom.a:esp_rom_systimer.* *libesp_rom.a:esp_rom_wdt.* *libesp_system.a:esp_err.* *libesp_system.a:esp_system_chip.* *libesp_system.a:ubsan.* *libgcc.a:_divsf3.* *libgcc.a:lib2funcs.* *libhal.a:cache_hal.* *libhal.a:i2c_hal_iram.* *libhal.a:ledc_hal_iram.* *libhal.a:mmu_hal.* *libhal.a:spi_flash_encrypt_hal_iram.* *libhal.a:spi_flash_hal_gpspi.* *libhal.a:spi_flash_hal_iram.* *libhal.a:systimer_hal.* *libhal.a:timer_hal.* *libheap.a:multi_heap.* *libheap.a:tlsf.* *liblog.a:log.* *liblog.a:log_freertos.* *libnewlib.a:abort.* *libnewlib.a:assert.* *libnewlib.a:heap.* *libnewlib.a:stdatomic.* *libsoc.a:lldesc.* *libspi_flash.a:flash_brownout_hook.* *libspi_flash.a:memspi_host_driver.* *libspi_flash.a:spi_flash_chip_boya.* *libspi_flash.a:spi_flash_chip_gd.* *libspi_flash.a:spi_flash_chip_generic.* *libspi_flash.a:spi_flash_chip_issi.* *libspi_flash.a:spi_flash_chip_mxic.* *libspi_flash.a:spi_flash_chip_mxic_opi.* *libspi_flash.a:spi_flash_chip_th.* *libspi_flash.a:spi_flash_chip_winbond.* *libspi_flash.a:spi_flash_hpm_enable.* *libspi_flash.a:spi_flash_oct_flash_init.* *libspi_flash.a:spi_flash_wrap.* *libxtensa.a:eri.* *libxtensa.a:xtensa_intr_asm.*) .text.*)
    *(.wifi0iram .wifi0iram.*)
    *(.wifiextrairam .wifiextrairam.*)
    *(.wifiorslpiram .wifiorslpiram.*)
    *(.wifirxiram .wifirxiram.*)
    *(.wifislpiram .wifislpiram.*)
    *(.wifislprxiram .wifislprxiram.*)
    *libdriver.a:gptimer.*(.literal.gptimer_del_timer .literal.gptimer_destroy .literal.gptimer_disable .literal.gptimer_enable .literal.gptimer_get_captured_count .literal.gptimer_get_raw_count .literal.gptimer_get_resolution .literal.gptimer_new_timer .literal.gptimer_register_event_callbacks .literal.gptimer_release_group_handle .literal.gptimer_set_alarm_action .literal.gptimer_set_raw_count .literal.gptimer_start .literal.gptimer_stop .text .text.gptimer_del_timer .text.gptimer_destroy .text.gptimer_disable .text.gptimer_enable .text.gptimer_get_captured_count .text.gptimer_get_raw_count .text.gptimer_get_resolution .text.gptimer_new_timer .text.gptimer_register_event_callbacks .text.gptimer_release_group_handle .text.gptimer_set_alarm_action .text.gptimer_set_raw_count .text.gptimer_start .text.gptimer_stop)
    *libesp_event.a:default_event_loop.*(.literal.esp_event_handler_instance_register .literal.esp_event_handler_instance_unregister .literal.esp_event_handler_register .literal.esp_event_handler_unregister .literal.esp_event_loop_create_default .literal.esp_event_loop_delete_default .literal.esp_event_post .text .text.esp_event_handler_instance_register .text.esp_event_handler_instance_unregister .text.esp_event_handler_register .text.esp_event_handler_unregister .text.esp_event_loop_create_default .text.esp_event_loop_delete_default .text.esp_event_post)
    *libesp_event.a:esp_event.*(.literal.base_node_add_handler .literal.esp_event_handler_instance_register_with .literal.esp_event_handler_instance_unregister_with .literal.esp_event_handler_register_with .literal.esp_event_handler_register_with_internal .literal.esp_event_handler_unregister_with .literal.esp_event_handler_unregister_with_internal .literal.esp_event_loop_create .literal.esp_event_loop_delete .literal.esp_event_loop_run .literal.esp_event_loop_run_task .literal.esp_event_post_to .literal.handler_instances_add .literal.handler_instances_remove .literal.handler_instances_remove_all .literal.loop_node_add_handler .text .text.base_node_add_handler .text.esp_event_dump .text.esp_event_handler_instance_register_with .text.esp_event_handler_instance_unregister_with .text.esp_event_handler_register_with .text.esp_event_handler_register_with_internal .text.esp_event_handler_unregister_with .text.esp_event_handler_unregister_with_internal .text.esp_event_loop_create .text.esp_event_loop_delete .text.esp_event_loop_run .text.esp_event_loop_run_task .text.esp_event_post_to .text.handler_instances_add .text.handler_instances_remove .text.handler_instances_remove_all .text.loop_node_add_handler)
    *libesp_hw_support.a:cpu.*(.literal.esp_cpu_set_watchpoint .text .text.esp_cpu_clear_breakpoint .text.esp_cpu_clear_watchpoint .text.esp_cpu_set_breakpoint .text.esp_cpu_set_watchpoint)
    *libesp_hw_support.a:esp_gpio_reserve.*(.text)
    *libesp_hw_support.a:sar_periph_ctrl.*(.literal.s_sar_power_acquire .literal.s_sar_power_release .literal.sar_periph_ctrl_adc_continuous_power_acquire .literal.sar_periph_ctrl_adc_continuous_power_release .literal.sar_periph_ctrl_adc_oneshot_power_acquire .literal.sar_periph_ctrl_adc_oneshot_power_release .literal.sar_periph_ctrl_init .literal.sar_periph_ctrl_power_disable .literal.sar_periph_ctrl_pwdet_power_acquire .literal.sar_periph_ctrl_pwdet_power_release .text .text.s_sar_power_acquire .text.s_sar_power_release .text.sar_periph_ctrl_adc_continuous_power_acquire .text.sar_periph_ctrl_adc_continuous_power_release .text.sar_periph_ctrl_adc_oneshot_power_acquire .text.sar_periph_ctrl_adc_oneshot_power_release .text.sar_periph_ctrl_init .text.sar_periph_ctrl_power_disable .text.sar_periph_ctrl_pwdet_power_acquire .text.sar_periph_ctrl_pwdet_power_release)
    *libesp_ringbuf.a:ringbuf.*(.literal.prvGetCurMaxSizeAllowSplit .text.prvGetCurMaxSizeAllowSplit)
    *libesp_ringbuf.a:ringbuf.*(.literal.prvGetCurMaxSizeByteBuf .text.prvGetCurMaxSizeByteBuf)
    *libesp_ringbuf.a:ringbuf.*(.literal.prvGetCurMaxSizeNoSplit .text.prvGetCurMaxSizeNoSplit)
    *libesp_ringbuf.a:ringbuf.*(.literal.prvInitializeNewRingbuffer .text.prvInitializeNewRingbuffer)
    *libesp_ringbuf.a:ringbuf.*(.literal.prvReceiveGeneric .text.prvReceiveGeneric)
    *libesp_ringbuf.a:ringbuf.*(.literal.prvSendAcquireGeneric .text.prvSendAcquireGeneric)
    *libesp_ringbuf.a:ringbuf.*(.literal.vRingbufferDelete .text.vRingbufferDelete)
    *libesp_ringbuf.a:ringbuf.*(.literal.vRingbufferGetInfo .text.vRingbufferGetInfo)
    *libesp_ringbuf.a:ringbuf.*(.literal.vRingbufferReturnItem .text.vRingbufferReturnItem)
    *libesp_ringbuf.a:ringbuf.*(.literal.xRingbufferAddToQueueSetRead .text.xRingbufferAddToQueueSetRead)
    *libesp_ringbuf.a:ringbuf.*(.literal.xRingbufferCreate .text.xRingbufferCreate)
    *libesp_ringbuf.a:ringbuf.*(.literal.xRingbufferCreateNoSplit .text.xRingbufferCreateNoSplit)
    *libesp_ringbuf.a:ringbuf.*(.literal.xRingbufferCreateStatic .text.xRingbufferCreateStatic)
    *libesp_ringbuf.a:ringbuf.*(.literal.xRingbufferGetCurFreeSize .text.xRingbufferGetCurFreeSize)
    *libesp_ringbuf.a:ringbuf.*(.literal.xRingbufferGetMaxItemSize .text.xRingbufferGetMaxItemSize)
    *libesp_ringbuf.a:ringbuf.*(.literal.xRingbufferPrintInfo .text.xRingbufferPrintInfo)
    *libesp_ringbuf.a:ringbuf.*(.literal.xRingbufferReceive .text.xRingbufferReceive)
    *libesp_ringbuf.a:ringbuf.*(.literal.xRingbufferReceiveSplit .text.xRingbufferReceiveSplit)
    *libesp_ringbuf.a:ringbuf.*(.literal.xRingbufferReceiveUpTo .text.xRingbufferReceiveUpTo)
    *libesp_ringbuf.a:ringbuf.*(.literal.xRingbufferRemoveFromQueueSetRead .text.xRingbufferRemoveFromQueueSetRead)
    *libesp_ringbuf.a:ringbuf.*(.literal.xRingbufferSend .text.xRingbufferSend)
    *libesp_ringbuf.a:ringbuf.*(.literal.xRingbufferSendAcquire .text.xRingbufferSendAcquire)
    *libesp_ringbuf.a:ringbuf.*(.literal.xRingbufferSendComplete .text.xRingbufferSendComplete)
    *libesp_system.a:esp_system_chip.*(.literal.esp_get_free_heap_size .literal.esp_get_free_internal_heap_size .literal.esp_get_idf_version .literal.esp_get_minimum_free_heap_size .text .text.esp_get_free_heap_size .text.esp_get_free_internal_heap_size .text.esp_get_idf_version .text.esp_get_minimum_free_heap_size)
    *libfreertos.a:app_startup.*(.literal .literal.* .text .text.*)
    *libfreertos.a:event_groups.*(.literal.vEventGroupClearBitsCallback .text.vEventGroupClearBitsCallback)
    *libfreertos.a:event_groups.*(.literal.vEventGroupDelete .text.vEventGroupDelete)
    *libfreertos.a:event_groups.*(.literal.vEventGroupSetBitsCallback .text.vEventGroupSetBitsCallback)
    *libfreertos.a:event_groups.*(.literal.xEventGroupClearBits .text.xEventGroupClearBits)
    *libfreertos.a:event_groups.*(.literal.xEventGroupCreate .text.xEventGroupCreate)
    *libfreertos.a:event_groups.*(.literal.xEventGroupCreateStatic .text.xEventGroupCreateStatic)
    *libfreertos.a:event_groups.*(.literal.xEventGroupSetBits .text.xEventGroupSetBits)
    *libfreertos.a:event_groups.*(.literal.xEventGroupSync .text.xEventGroupSync)
    *libfreertos.a:event_groups.*(.literal.xEventGroupWaitBits .text.xEventGroupWaitBits)
    *libfreertos.a:heap_idf.*(.literal.pvPortMalloc .text.pvPortMalloc)
    *libfreertos.a:heap_idf.*(.literal.vPortFree .text.vPortFree)
    *libfreertos.a:heap_idf.*(.literal.xPortCheckValidTCBMem .text.xPortCheckValidTCBMem)
    *libfreertos.a:heap_idf.*(.literal.xPortGetFreeHeapSize .text.xPortGetFreeHeapSize)
    *libfreertos.a:heap_idf.*(.literal.xPortGetMinimumEverFreeHeapSize .text.xPortGetMinimumEverFreeHeapSize)
    *libfreertos.a:heap_idf.*(.literal.xPortcheckValidStackMem .text.xPortcheckValidStackMem)
    *libfreertos.a:idf_additions.*(.literal .literal.* .text .text.*)
    *libfreertos.a:list.*(.literal.vListInitialise .text.vListInitialise)
    *libfreertos.a:list.*(.literal.vListInitialiseItem .text.vListInitialiseItem)
    *libfreertos.a:port.*(.literal.pxPortInitialiseStack .text.pxPortInitialiseStack)
    *libfreertos.a:port.*(.literal.vPortCleanUpCoprocArea .text.vPortCleanUpCoprocArea)
    *libfreertos.a:port.*(.literal.xPortGetTickRateHz .text.xPortGetTickRateHz)
    *libfreertos.a:port.*(.literal.xPortStartScheduler .text.xPortStartScheduler)
    *libfreertos.a:port_common.*(.literal.vApplicationGetIdleTaskMemory .text.vApplicationGetIdleTaskMemory)
    *libfreertos.a:port_common.*(.literal.vApplicationGetTimerTaskMemory .text.vApplicationGetTimerTaskMemory)
    *libfreertos.a:queue.*(.literal.prvInitialiseMutex .text.prvInitialiseMutex)
    *libfreertos.a:queue.*(.literal.uxQueueMessagesWaiting .text.uxQueueMessagesWaiting)
    *libfreertos.a:queue.*(.literal.uxQueueSpacesAvailable .text.uxQueueSpacesAvailable)
    *libfreertos.a:queue.*(.literal.vQueueDelete .text.vQueueDelete)
    *libfreertos.a:queue.*(.literal.vQueueWaitForMessageRestricted .text.vQueueWaitForMessageRestricted)
    *libfreertos.a:queue.*(.literal.xQueueAddToSet .text.xQueueAddToSet)
    *libfreertos.a:queue.*(.literal.xQueueCreateCountingSemaphore .text.xQueueCreateCountingSemaphore)
    *libfreertos.a:queue.*(.literal.xQueueCreateCountingSemaphoreStatic .text.xQueueCreateCountingSemaphoreStatic)
    *libfreertos.a:queue.*(.literal.xQueueCreateMutex .text.xQueueCreateMutex)
    *libfreertos.a:queue.*(.literal.xQueueCreateMutexStatic .text.xQueueCreateMutexStatic)
    *libfreertos.a:queue.*(.literal.xQueueCreateSet .text.xQueueCreateSet)
    *libfreertos.a:queue.*(.literal.xQueueGenericCreate .text.xQueueGenericCreate)
    *libfreertos.a:queue.*(.literal.xQueueGenericCreateStatic .text.xQueueGenericCreateStatic)
    *libfreertos.a:queue.*(.literal.xQueueGenericReset .text.xQueueGenericReset)
    *libfreertos.a:queue.*(.literal.xQueueGenericSend .text.xQueueGenericSend)
    *libfreertos.a:queue.*(.literal.xQueueGetMutexHolder .text.xQueueGetMutexHolder)
    *libfreertos.a:queue.*(.literal.xQueueGiveMutexRecursive .text.xQueueGiveMutexRecursive)
    *libfreertos.a:queue.*(.literal.xQueuePeek .text.xQueuePeek)
    *libfreertos.a:queue.*(.literal.xQueueReceive .text.xQueueReceive)
    *libfreertos.a:queue.*(.literal.xQueueRemoveFromSet .text.xQueueRemoveFromSet)
    *libfreertos.a:queue.*(.literal.xQueueSelectFromSet .text.xQueueSelectFromSet)
    *libfreertos.a:queue.*(.literal.xQueueSemaphoreTake .text.xQueueSemaphoreTake)
    *libfreertos.a:queue.*(.literal.xQueueTakeMutexRecursive .text.xQueueTakeMutexRecursive)
    *libfreertos.a:stream_buffer.*(.literal.prvInitialiseNewStreamBuffer .text.prvInitialiseNewStreamBuffer)
    *libfreertos.a:stream_buffer.*(.literal.prvReadBytesFromBuffer .text.prvReadBytesFromBuffer)
    *libfreertos.a:stream_buffer.*(.literal.prvWriteBytesToBuffer .text.prvWriteBytesToBuffer)
    *libfreertos.a:stream_buffer.*(.literal.vStreamBufferDelete .text.vStreamBufferDelete)
    *libfreertos.a:stream_buffer.*(.literal.xStreamBufferBytesAvailable .text.xStreamBufferBytesAvailable)
    *libfreertos.a:stream_buffer.*(.literal.xStreamBufferGenericCreate .text.xStreamBufferGenericCreate)
    *libfreertos.a:stream_buffer.*(.literal.xStreamBufferGenericCreateStatic .text.xStreamBufferGenericCreateStatic)
    *libfreertos.a:stream_buffer.*(.literal.xStreamBufferIsEmpty .text.xStreamBufferIsEmpty)
    *libfreertos.a:stream_buffer.*(.literal.xStreamBufferIsFull .text.xStreamBufferIsFull)
    *libfreertos.a:stream_buffer.*(.literal.xStreamBufferNextMessageLengthBytes .text.xStreamBufferNextMessageLengthBytes)
    *libfreertos.a:stream_buffer.*(.literal.xStreamBufferReceive .text.xStreamBufferReceive)
    *libfreertos.a:stream_buffer.*(.literal.xStreamBufferReset .text.xStreamBufferReset)
    *libfreertos.a:stream_buffer.*(.literal.xStreamBufferSend .text.xStreamBufferSend)
    *libfreertos.a:stream_buffer.*(.literal.xStreamBufferSetTriggerLevel .text.xStreamBufferSetTriggerLevel)
    *libfreertos.a:tasks.*(.literal.eTaskGetState .text.eTaskGetState)
    *libfreertos.a:tasks.*(.literal.pcTaskGetName .text.pcTaskGetName)
    *libfreertos.a:tasks.*(.literal.prvAddCurrentTaskToDelayedList .text.prvAddCurrentTaskToDelayedList)
    *libfreertos.a:tasks.*(.literal.prvAddNewTaskToReadyList .text.prvAddNewTaskToReadyList)
    *libfreertos.a:tasks.*(.literal.prvDeleteTCB .text.prvDeleteTCB)
    *libfreertos.a:tasks.*(.literal.prvDeleteTLS .text.prvDeleteTLS)
    *libfreertos.a:tasks.*(.literal.prvIdleTask .text.prvIdleTask)
    *libfreertos.a:tasks.*(.literal.prvSearchForNameWithinSingleList .text.prvSearchForNameWithinSingleList)
    *libfreertos.a:tasks.*(.literal.prvTaskPriorityRaise .text.prvTaskPriorityRaise)
    *libfreertos.a:tasks.*(.literal.prvTaskPriorityRestore .text.prvTaskPriorityRestore)
    *libfreertos.a:tasks.*(.literal.pvTaskGetThreadLocalStoragePointer .text.pvTaskGetThreadLocalStoragePointer)
    *libfreertos.a:tasks.*(.literal.pvTaskIncrementMutexHeldCount .text.pvTaskIncrementMutexHeldCount)
    *libfreertos.a:tasks.*(.literal.pxTaskGetStackStart .text.pxTaskGetStackStart)
    *libfreertos.a:tasks.*(.literal.ulTaskGenericNotifyTake .text.ulTaskGenericNotifyTake)
    *libfreertos.a:tasks.*(.literal.ulTaskGenericNotifyValueClear .text.ulTaskGenericNotifyValueClear)
    *libfreertos.a:tasks.*(.literal.ulTaskNotifyTake .text.ulTaskNotifyTake)
    *libfreertos.a:tasks.*(.literal.uxTaskGetNumberOfTasks .text.uxTaskGetNumberOfTasks)
    *libfreertos.a:tasks.*(.literal.uxTaskGetStackHighWaterMark .text.uxTaskGetStackHighWaterMark)
    *libfreertos.a:tasks.*(.literal.uxTaskGetStackHighWaterMark2 .text.uxTaskGetStackHighWaterMark2)
    *libfreertos.a:tasks.*(.literal.uxTaskPriorityGet .text.uxTaskPriorityGet)
    *libfreertos.a:tasks.*(.literal.uxTaskResetEventItemValue .text.uxTaskResetEventItemValue)
    *libfreertos.a:tasks.*(.literal.vTaskDelay .text.vTaskDelay)
    *libfreertos.a:tasks.*(.literal.vTaskDelayUntil .text.vTaskDelayUntil)
    *libfreertos.a:tasks.*(.literal.vTaskDelete .text.vTaskDelete)
    *libfreertos.a:tasks.*(.literal.vTaskEndScheduler .text.vTaskEndScheduler)
    *libfreertos.a:tasks.*(.literal.vTaskInternalSetTimeOutState .text.vTaskInternalSetTimeOutState)
    *libfreertos.a:tasks.*(.literal.vTaskMissedYield .text.vTaskMissedYield)
    *libfreertos.a:tasks.*(.literal.vTaskPlaceOnEventList .text.vTaskPlaceOnEventList)
    *libfreertos.a:tasks.*(.literal.vTaskPlaceOnEventListRestricted .text.vTaskPlaceOnEventListRestricted)
    *libfreertos.a:tasks.*(.literal.vTaskPlaceOnUnorderedEventList .text.vTaskPlaceOnUnorderedEventList)
    *libfreertos.a:tasks.*(.literal.vTaskPriorityDisinheritAfterTimeout .text.vTaskPriorityDisinheritAfterTimeout)
    *libfreertos.a:tasks.*(.literal.vTaskPrioritySet .text.vTaskPrioritySet)
    *libfreertos.a:tasks.*(.literal.vTaskReleaseKernelLock .text.vTaskReleaseKernelLock)
    *libfreertos.a:tasks.*(.literal.vTaskRemoveFromUnorderedEventList .text.vTaskRemoveFromUnorderedEventList)
    *libfreertos.a:tasks.*(.literal.vTaskResume .text.vTaskResume)
    *libfreertos.a:tasks.*(.literal.vTaskSetThreadLocalStoragePointer .text.vTaskSetThreadLocalStoragePointer)
    *libfreertos.a:tasks.*(.literal.vTaskSetThreadLocalStoragePointerAndDelCallback .text.vTaskSetThreadLocalStoragePointerAndDelCallback)
    *libfreertos.a:tasks.*(.literal.vTaskSetTimeOutState .text.vTaskSetTimeOutState)
    *libfreertos.a:tasks.*(.literal.vTaskStartScheduler .text.vTaskStartScheduler)
    *libfreertos.a:tasks.*(.literal.vTaskSuspend .text.vTaskSuspend)
    *libfreertos.a:tasks.*(.literal.vTaskSuspendAll .text.vTaskSuspendAll)
    *libfreertos.a:tasks.*(.literal.vTaskTakeKernelLock .text.vTaskTakeKernelLock)
    *libfreertos.a:tasks.*(.literal.xTaskAbortDelay .text.xTaskAbortDelay)
    *libfreertos.a:tasks.*(.literal.xTaskCheckForTimeOut .text.xTaskCheckForTimeOut)
    *libfreertos.a:tasks.*(.literal.xTaskCreatePinnedToCore .text.xTaskCreatePinnedToCore)
    *libfreertos.a:tasks.*(.literal.xTaskCreateStaticPinnedToCore .text.xTaskCreateStaticPinnedToCore)
    *libfreertos.a:tasks.*(.literal.xTaskDelayUntil .text.xTaskDelayUntil)
    *libfreertos.a:tasks.*(.literal.xTaskGenericNotify .text.xTaskGenericNotify)
    *libfreertos.a:tasks.*(.literal.xTaskGenericNotifyStateClear .text.xTaskGenericNotifyStateClear)
    *libfreertos.a:tasks.*(.literal.xTaskGenericNotifyWait .text.xTaskGenericNotifyWait)
    *libfreertos.a:tasks.*(.literal.xTaskGetAffinity .text.xTaskGetAffinity)
    *libfreertos.a:tasks.*(.literal.xTaskGetCurrentTaskHandle .text.xTaskGetCurrentTaskHandle)
    *libfreertos.a:tasks.*(.literal.xTaskGetCurrentTaskHandleForCPU .text.xTaskGetCurrentTaskHandleForCPU)
    *libfreertos.a:tasks.*(.literal.xTaskGetHandle .text.xTaskGetHandle)
    *libfreertos.a:tasks.*(.literal.xTaskGetIdleTaskHandle .text.xTaskGetIdleTaskHandle)
    *libfreertos.a:tasks.*(.literal.xTaskGetIdleTaskHandleForCPU .text.xTaskGetIdleTaskHandleForCPU)
    *libfreertos.a:tasks.*(.literal.xTaskNotifyWait .text.xTaskNotifyWait)
    *libfreertos.a:tasks.*(.literal.xTaskPriorityDisinherit .text.xTaskPriorityDisinherit)
    *libfreertos.a:tasks.*(.literal.xTaskPriorityInherit .text.xTaskPriorityInherit)
    *libfreertos.a:tasks.*(.literal.xTaskResumeAll .text.xTaskResumeAll)
    *libfreertos.a:timers.*(.literal.pcTimerGetName .text.pcTimerGetName)
    *libfreertos.a:timers.*(.literal.prvCheckForValidListAndQueue .text.prvCheckForValidListAndQueue)
    *libfreertos.a:timers.*(.literal.prvInsertTimerInActiveList .text.prvInsertTimerInActiveList)
    *libfreertos.a:timers.*(.literal.prvSampleTimeNow .text.prvSampleTimeNow)
    *libfreertos.a:timers.*(.literal.prvTimerTask .text.prvTimerTask)
    *libfreertos.a:timers.*(.literal.pvTimerGetTimerID .text.pvTimerGetTimerID)
    *libfreertos.a:timers.*(.literal.uxTimerGetReloadMode .text.uxTimerGetReloadMode)
    *libfreertos.a:timers.*(.literal.vTimerSetReloadMode .text.vTimerSetReloadMode)
    *libfreertos.a:timers.*(.literal.vTimerSetTimerID .text.vTimerSetTimerID)
    *libfreertos.a:timers.*(.literal.xTimerCreate .text.xTimerCreate)
    *libfreertos.a:timers.*(.literal.xTimerCreateStatic .text.xTimerCreateStatic)
    *libfreertos.a:timers.*(.literal.xTimerCreateTimerTask .text.xTimerCreateTimerTask)
    *libfreertos.a:timers.*(.literal.xTimerGenericCommand .text.xTimerGenericCommand)
    *libfreertos.a:timers.*(.literal.xTimerGetExpiryTime .text.xTimerGetExpiryTime)
    *libfreertos.a:timers.*(.literal.xTimerGetPeriod .text.xTimerGetPeriod)
    *libfreertos.a:timers.*(.literal.xTimerGetTimerDaemonTaskHandle .text.xTimerGetTimerDaemonTaskHandle)
    *libfreertos.a:timers.*(.literal.xTimerIsTimerActive .text.xTimerIsTimerActive)
    *libfreertos.a:timers.*(.literal.xTimerPendFunctionCall .text.xTimerPendFunctionCall)
    *libhal.a:timer_hal.*(.literal.timer_hal_deinit .literal.timer_hal_init .literal.timer_hal_set_counter_value .text .text.timer_hal_deinit .text.timer_hal_init .text.timer_hal_set_counter_value)
    *libheap.a:multi_heap.*(.literal.multi_heap_check .literal.multi_heap_dump .literal.multi_heap_dump_tlsf .literal.multi_heap_get_info_impl .literal.multi_heap_register_impl .text .text.multi_heap_check .text.multi_heap_dump .text.multi_heap_dump_tlsf .text.multi_heap_free_size_impl .text.multi_heap_get_block_owner .text.multi_heap_get_info_impl .text.multi_heap_get_info_tlsf .text.multi_heap_minimum_free_size_impl .text.multi_heap_register_impl)
    *libheap.a:tlsf.*(.literal.default_walker .literal.integrity_walker .literal.tlsf_add_pool .literal.tlsf_check .literal.tlsf_check_pool .literal.tlsf_create .literal.tlsf_create_with_pool .literal.tlsf_remove_pool .literal.tlsf_walk_pool .text .text.default_walker .text.integrity_walker .text.tlsf_add_pool .text.tlsf_check .text.tlsf_check_pool .text.tlsf_create .text.tlsf_create_with_pool .text.tlsf_destroy .text.tlsf_fit_size .text.tlsf_pool_overhead .text.tlsf_remove_pool .text.tlsf_walk_pool)
    *liblog.a:log.*(.literal.esp_log_level_get .literal.esp_log_level_set .literal.esp_log_set_vprintf .literal.esp_log_writev .literal.fix_cache_generation_overflow .literal.heap_bubble_down .literal.s_log_level_get_and_unlock .text .text.esp_log_level_get .text.esp_log_level_set .text.esp_log_set_vprintf .text.esp_log_writev .text.fix_cache_generation_overflow .text.heap_bubble_down .text.s_log_level_get_and_unlock)
    *liblog.a:log_freertos.*(.literal.esp_log_system_timestamp .text .text.esp_log_system_timestamp)

    *(.stub .gnu.warning .gnu.linkonce.literal.* .gnu.linkonce.t.*.literal .gnu.linkonce.t.*)
    *(.irom0.text) /* catch stray ICACHE_RODATA_ATTR */
    *(.fini.literal)
    *(.fini)
    *(.gnu.version)

    /** CPU will try to prefetch up to 16 bytes of
      * of instructions. This means that any configuration (e.g. MMU, PMS) must allow
      * safe access to up to 16 bytes after the last real instruction, add
      * dummy bytes to ensure this
      */
    . += _esp_flash_mmap_prefetch_pad_size;

    _text_end = ABSOLUTE(.);
    _instruction_reserved_end = ABSOLUTE(.);  /* This is a symbol marking the flash.text end, this can be used for mmu driver to maintain virtual address */
    _etext = .;

    /**
     * Similar to _iram_start, this symbol goes here so it is
     * resolved by addr2line in preference to the first symbol in
     * the flash.text segment.
     */
    _flash_cache_start = ABSOLUTE(0);
  } > default_code_seg

  /**
   * This dummy section represents the .flash.text section but in default_rodata_seg.
   * Thus, it must have its alignment and (at least) its size.
   */
  .flash_rodata_dummy (NOLOAD):
  {
    _flash_rodata_dummy_start = ABSOLUTE(.);
    /* Start at the same alignment constraint than .flash.text */
    . = ALIGN(ALIGNOF(.flash.text));
    /* Create an empty gap as big as .flash.text section */
    . = . + SIZEOF(.flash.text);
    /* Prepare the alignment of the section above. Few bytes (0x20) must be
     * added for the mapping header. */
    . = ALIGN(_esp_mmu_block_size) + 0x20;
  } > default_rodata_seg

  .flash.appdesc : ALIGN(0x10)
  {
    _rodata_reserved_start = ABSOLUTE(.);  /* This is a symbol marking the flash.rodata start, this can be used for mmu driver to maintain virtual address */
    _rodata_start = ABSOLUTE(.);

    *(.rodata_desc .rodata_desc.*)               /* Should be the first.  App version info.        DO NOT PUT ANYTHING BEFORE IT! */
    *(.rodata_custom_desc .rodata_custom_desc.*) /* Should be the second. Custom app version info. DO NOT PUT ANYTHING BEFORE IT! */

    /* Create an empty gap within this section. Thanks to this, the end of this
     * section will match .flah.rodata's begin address. Thus, both sections
     * will be merged when creating the final bin image. */
    . = ALIGN(ALIGNOF(.flash.rodata));
  } >default_rodata_seg

  .flash.rodata : ALIGN(0x10)
  {
    _flash_rodata_start = ABSOLUTE(.);

    *(EXCLUDE_FILE(*libgcov.a *libphy.a *libapp_trace.a:app_trace.* *libapp_trace.a:app_trace_util.* *libapp_trace.a:port_uart.* *libesp_hw_support.a:esp_memory_utils.* *libesp_hw_support.a:mspi_timing_config.* *libesp_hw_support.a:mspi_timing_tuning.* *libesp_hw_support.a:rtc_clk.* *libesp_hw_support.a:sleep_console.* *libesp_hw_support.a:systimer.* *libesp_mm.a:esp_cache.* *libesp_psram.a:esp_psram_impl_octal.* *libesp_psram.a:mmu_psram_flash.* *libesp_rom.a:esp_rom_cache_esp32s2_esp32s3.* *libesp_rom.a:esp_rom_cache_writeback_esp32s3.* *libesp_rom.a:esp_rom_spiflash.* *libesp_rom.a:esp_rom_systimer.* *libesp_rom.a:esp_rom_wdt.* *libesp_system.a:esp_err.* *libesp_system.a:ubsan.* *libfreertos.a:FreeRTOS-openocd.* *libgcc.a:_divsf3.* *libhal.a:cache_hal.* *libhal.a:i2c_hal_iram.* *libhal.a:ledc_hal_iram.* *libhal.a:mmu_hal.* *libhal.a:spi_flash_encrypt_hal_iram.* *libhal.a:spi_flash_hal_gpspi.* *libhal.a:spi_flash_hal_iram.* *libhal.a:systimer_hal.* *libnewlib.a:abort.* *libnewlib.a:assert.* *libnewlib.a:heap.* *libnewlib.a:stdatomic.* *libsoc.a:lldesc.* *libspi_flash.a:flash_brownout_hook.* *libspi_flash.a:memspi_host_driver.* *libspi_flash.a:spi_flash_chip_boya.* *libspi_flash.a:spi_flash_chip_gd.* *libspi_flash.a:spi_flash_chip_generic.* *libspi_flash.a:spi_flash_chip_issi.* *libspi_flash.a:spi_flash_chip_mxic.* *libspi_flash.a:spi_flash_chip_mxic_opi.* *libspi_flash.a:spi_flash_chip_th.* *libspi_flash.a:spi_flash_chip_winbond.* *libspi_flash.a:spi_flash_hpm_enable.* *libspi_flash.a:spi_flash_oct_flash_init.* *libspi_flash.a:spi_flash_wrap.*) .rodata EXCLUDE_FILE(*libgcov.a *libphy.a *libapp_trace.a:app_trace.* *libapp_trace.a:app_trace_util.* *libapp_trace.a:port_uart.* *libesp_hw_support.a:esp_memory_utils.* *libesp_hw_support.a:mspi_timing_config.* *libesp_hw_support.a:mspi_timing_tuning.* *libesp_hw_support.a:rtc_clk.* *libesp_hw_support.a:sleep_console.* *libesp_hw_support.a:systimer.* *libesp_mm.a:esp_cache.* *libesp_psram.a:esp_psram_impl_octal.* *libesp_psram.a:mmu_psram_flash.* *libesp_rom.a:esp_rom_cache_esp32s2_esp32s3.* *libesp_rom.a:esp_rom_cache_writeback_esp32s3.* *libesp_rom.a:esp_rom_spiflash.* *libesp_rom.a:esp_rom_systimer.* *libesp_rom.a:esp_rom_wdt.* *libesp_system.a:esp_err.* *libesp_system.a:ubsan.* *libfreertos.a:FreeRTOS-openocd.* *libgcc.a:_divsf3.* *libhal.a:cache_hal.* *libhal.a:i2c_hal_iram.* *libhal.a:ledc_hal_iram.* *libhal.a:mmu_hal.* *libhal.a:spi_flash_encrypt_hal_iram.* *libhal.a:spi_flash_hal_gpspi.* *libhal.a:spi_flash_hal_iram.* *libhal.a:systimer_hal.* *libnewlib.a:abort.* *libnewlib.a:assert.* *libnewlib.a:heap.* *libnewlib.a:stdatomic.* *libsoc.a:lldesc.* *libspi_flash.a:flash_brownout_hook.* *libspi_flash.a:memspi_host_driver.* *libspi_flash.a:spi_flash_chip_boya.* *libspi_flash.a:spi_flash_chip_gd.* *libspi_flash.a:spi_flash_chip_generic.* *libspi_flash.a:spi_flash_chip_issi.* *libspi_flash.a:spi_flash_chip_mxic.* *libspi_flash.a:spi_flash_chip_mxic_opi.* *libspi_flash.a:spi_flash_chip_th.* *libspi_flash.a:spi_flash_chip_winbond.* *libspi_flash.a:spi_flash_hpm_enable.* *libspi_flash.a:spi_flash_oct_flash_init.* *libspi_flash.a:spi_flash_wrap.*) .rodata.* EXCLUDE_FILE(*libgcov.a *libphy.a *libapp_trace.a:app_trace.* *libapp_trace.a:app_trace_util.* *libapp_trace.a:port_uart.* *libesp_hw_support.a:esp_memory_utils.* *libesp_hw_support.a:mspi_timing_config.* *libesp_hw_support.a:mspi_timing_tuning.* *libesp_hw_support.a:rtc_clk.* *libesp_hw_support.a:sleep_console.* *libesp_hw_support.a:systimer.* *libesp_mm.a:esp_cache.* *libesp_psram.a:esp_psram_impl_octal.* *libesp_psram.a:mmu_psram_flash.* *libesp_rom.a:esp_rom_cache_esp32s2_esp32s3.* *libesp_rom.a:esp_rom_cache_writeback_esp32s3.* *libesp_rom.a:esp_rom_spiflash.* *libesp_rom.a:esp_rom_systimer.* *libesp_rom.a:esp_rom_wdt.* *libesp_system.a:esp_err.* *libesp_system.a:ubsan.* *libfreertos.a:FreeRTOS-openocd.* *libgcc.a:_divsf3.* *libhal.a:cache_hal.* *libhal.a:i2c_hal_iram.* *libhal.a:ledc_hal_iram.* *libhal.a:mmu_hal.* *libhal.a:spi_flash_encrypt_hal_iram.* *libhal.a:spi_flash_hal_gpspi.* *libhal.a:spi_flash_hal_iram.* *libhal.a:systimer_hal.* *libnewlib.a:abort.* *libnewlib.a:assert.* *libnewlib.a:heap.* *libnewlib.a:stdatomic.* *libsoc.a:lldesc.* *libspi_flash.a:flash_brownout_hook.* *libspi_flash.a:memspi_host_driver.* *libspi_flash.a:spi_flash_chip_boya.* *libspi_flash.a:spi_flash_chip_gd.* *libspi_flash.a:spi_flash_chip_generic.* *libspi_flash.a:spi_flash_chip_issi.* *libspi_flash.a:spi_flash_chip_mxic.* *libspi_flash.a:spi_flash_chip_mxic_opi.* *libspi_flash.a:spi_flash_chip_th.* *libspi_flash.a:spi_flash_chip_winbond.* *libspi_flash.a:spi_flash_hpm_enable.* *libspi_flash.a:spi_flash_oct_flash_init.* *libspi_flash.a:spi_flash_wrap.*) .sdata2 EXCLUDE_FILE(*libgcov.a *libphy.a *libapp_trace.a:app_trace.* *libapp_trace.a:app_trace_util.* *libapp_trace.a:port_uart.* *libesp_hw_support.a:esp_memory_utils.* *libesp_hw_support.a:mspi_timing_config.* *libesp_hw_support.a:mspi_timing_tuning.* *libesp_hw_support.a:rtc_clk.* *libesp_hw_support.a:sleep_console.* *libesp_hw_support.a:systimer.* *libesp_mm.a:esp_cache.* *libesp_psram.a:esp_psram_impl_octal.* *libesp_psram.a:mmu_psram_flash.* *libesp_rom.a:esp_rom_cache_esp32s2_esp32s3.* *libesp_rom.a:esp_rom_cache_writeback_esp32s3.* *libesp_rom.a:esp_rom_spiflash.* *libesp_rom.a:esp_rom_systimer.* *libesp_rom.a:esp_rom_wdt.* *libesp_system.a:esp_err.* *libesp_system.a:ubsan.* *libfreertos.a:FreeRTOS-openocd.* *libgcc.a:_divsf3.* *libhal.a:cache_hal.* *libhal.a:i2c_hal_iram.* *libhal.a:ledc_hal_iram.* *libhal.a:mmu_hal.* *libhal.a:spi_flash_encrypt_hal_iram.* *libhal.a:spi_flash_hal_gpspi.* *libhal.a:spi_flash_hal_iram.* *libhal.a:systimer_hal.* *libnewlib.a:abort.* *libnewlib.a:assert.* *libnewlib.a:heap.* *libnewlib.a:stdatomic.* *libsoc.a:lldesc.* *libspi_flash.a:flash_brownout_hook.* *libspi_flash.a:memspi_host_driver.* *libspi_flash.a:spi_flash_chip_boya.* *libspi_flash.a:spi_flash_chip_gd.* *libspi_flash.a:spi_flash_chip_generic.* *libspi_flash.a:spi_flash_chip_issi.* *libspi_flash.a:spi_flash_chip_mxic.* *libspi_flash.a:spi_flash_chip_mxic_opi.* *libspi_flash.a:spi_flash_chip_th.* *libspi_flash.a:spi_flash_chip_winbond.* *libspi_flash.a:spi_flash_hpm_enable.* *libspi_flash.a:spi_flash_oct_flash_init.* *libspi_flash.a:spi_flash_wrap.*) .sdata2.* EXCLUDE_FILE(*libgcov.a *libphy.a *libapp_trace.a:app_trace.* *libapp_trace.a:app_trace_util.* *libapp_trace.a:port_uart.* *libesp_hw_support.a:esp_memory_utils.* *libesp_hw_support.a:mspi_timing_config.* *libesp_hw_support.a:mspi_timing_tuning.* *libesp_hw_support.a:rtc_clk.* *libesp_hw_support.a:sleep_console.* *libesp_hw_support.a:systimer.* *libesp_mm.a:esp_cache.* *libesp_psram.a:esp_psram_impl_octal.* *libesp_psram.a:mmu_psram_flash.* *libesp_rom.a:esp_rom_cache_esp32s2_esp32s3.* *libesp_rom.a:esp_rom_cache_writeback_esp32s3.* *libesp_rom.a:esp_rom_spiflash.* *libesp_rom.a:esp_rom_systimer.* *libesp_rom.a:esp_rom_wdt.* *libesp_system.a:esp_err.* *libesp_system.a:ubsan.* *libfreertos.a:FreeRTOS-openocd.* *libgcc.a:_divsf3.* *libhal.a:cache_hal.* *libhal.a:i2c_hal_iram.* *libhal.a:ledc_hal_iram.* *libhal.a:mmu_hal.* *libhal.a:spi_flash_encrypt_hal_iram.* *libhal.a:spi_flash_hal_gpspi.* *libhal.a:spi_flash_hal_iram.* *libhal.a:systimer_hal.* *libnewlib.a:abort.* *libnewlib.a:assert.* *libnewlib.a:heap.* *libnewlib.a:stdatomic.* *libsoc.a:lldesc.* *libspi_flash.a:flash_brownout_hook.* *libspi_flash.a:memspi_host_driver.* *libspi_flash.a:spi_flash_chip_boya.* *libspi_flash.a:spi_flash_chip_gd.* *libspi_flash.a:spi_flash_chip_generic.* *libspi_flash.a:spi_flash_chip_issi.* *libspi_flash.a:spi_flash_chip_mxic.* *libspi_flash.a:spi_flash_chip_mxic_opi.* *libspi_flash.a:spi_flash_chip_th.* *libspi_flash.a:spi_flash_chip_winbond.* *libspi_flash.a:spi_flash_hpm_enable.* *libspi_flash.a:spi_flash_oct_flash_init.* *libspi_flash.a:spi_flash_wrap.*) .srodata EXCLUDE_FILE(*libgcov.a *libphy.a *libapp_trace.a:app_trace.* *libapp_trace.a:app_trace_util.* *libapp_trace.a:port_uart.* *libesp_hw_support.a:esp_memory_utils.* *libesp_hw_support.a:mspi_timing_config.* *libesp_hw_support.a:mspi_timing_tuning.* *libesp_hw_support.a:rtc_clk.* *libesp_hw_support.a:sleep_console.* *libesp_hw_support.a:systimer.* *libesp_mm.a:esp_cache.* *libesp_psram.a:esp_psram_impl_octal.* *libesp_psram.a:mmu_psram_flash.* *libesp_rom.a:esp_rom_cache_esp32s2_esp32s3.* *libesp_rom.a:esp_rom_cache_writeback_esp32s3.* *libesp_rom.a:esp_rom_spiflash.* *libesp_rom.a:esp_rom_systimer.* *libesp_rom.a:esp_rom_wdt.* *libesp_system.a:esp_err.* *libesp_system.a:ubsan.* *libfreertos.a:FreeRTOS-openocd.* *libgcc.a:_divsf3.* *libhal.a:cache_hal.* *libhal.a:i2c_hal_iram.* *libhal.a:ledc_hal_iram.* *libhal.a:mmu_hal.* *libhal.a:spi_flash_encrypt_hal_iram.* *libhal.a:spi_flash_hal_gpspi.* *libhal.a:spi_flash_hal_iram.* *libhal.a:systimer_hal.* *libnewlib.a:abort.* *libnewlib.a:assert.* *libnewlib.a:heap.* *libnewlib.a:stdatomic.* *libsoc.a:lldesc.* *libspi_flash.a:flash_brownout_hook.* *libspi_flash.a:memspi_host_driver.* *libspi_flash.a:spi_flash_chip_boya.* *libspi_flash.a:spi_flash_chip_gd.* *libspi_flash.a:spi_flash_chip_generic.* *libspi_flash.a:spi_flash_chip_issi.* *libspi_flash.a:spi_flash_chip_mxic.* *libspi_flash.a:spi_flash_chip_mxic_opi.* *libspi_flash.a:spi_flash_chip_th.* *libspi_flash.a:spi_flash_chip_winbond.* *libspi_flash.a:spi_flash_hpm_enable.* *libspi_flash.a:spi_flash_oct_flash_init.* *libspi_flash.a:spi_flash_wrap.*) .srodata.*)
    *(.rodata_wlog_error .rodata_wlog_error.*)
    *(.rodata_wlog_info .rodata_wlog_info.*)
    *(.rodata_wlog_warning .rodata_wlog_warning.*)

    *(.irom1.text) /* catch stray ICACHE_RODATA_ATTR */
    *(.gnu.linkonce.r.*)
    *(.rodata1)
    __XT_EXCEPTION_TABLE_ = ABSOLUTE(.);
    *(.xt_except_table)
    *(.gcc_except_table .gcc_except_table.*)
    *(.gnu.linkonce.e.*)
    *(.gnu.version_r)
    . = (. + 3) & ~ 3;
    __eh_frame = ABSOLUTE(.);
    KEEP(*(.eh_frame))
    . = (. + 7) & ~ 3;
    /* C++ constructor and destructor tables */
    /* Don't include anything from crtbegin.o or crtend.o, as IDF doesn't use toolchain crt */
    __init_array_start = ABSOLUTE(.);
    KEEP (*(EXCLUDE_FILE (*crtend.* *crtbegin.*) .ctors SORT(.ctors.*)))
    __init_array_end = ABSOLUTE(.);
    KEEP (*crtbegin.*(.dtors))
    KEEP (*(EXCLUDE_FILE (*crtend.*) .dtors))
    KEEP (*(SORT(.dtors.*)))
    KEEP (*(.dtors))
    /* C++ exception handlers table: */
    __XT_EXCEPTION_DESCS_ = ABSOLUTE(.);
    *(.xt_except_desc)
    *(.gnu.linkonce.h.*)
    __XT_EXCEPTION_DESCS_END__ = ABSOLUTE(.);
    *(.xt_except_desc_end)
    *(.dynamic)
    *(.gnu.version_d)
    /* Addresses of memory regions reserved via SOC_RESERVE_MEMORY_REGION() */
    soc_reserved_memory_region_start = ABSOLUTE(.);
    KEEP (*(.reserved_memory_address))
    soc_reserved_memory_region_end = ABSOLUTE(.);
    /* System init functions registered via ESP_SYSTEM_INIT_FN */
    _esp_system_init_fn_array_start = ABSOLUTE(.);
    KEEP (*(SORT_BY_INIT_PRIORITY(.esp_system_init_fn.*)))
    _esp_system_init_fn_array_end = ABSOLUTE(.);
    _rodata_end = ABSOLUTE(.);
    /* Literals are also RO data. */
    _lit4_start = ABSOLUTE(.);
    *(*.lit4)
    *(.lit4.*)
    *(.gnu.linkonce.lit4.*)
    _lit4_end = ABSOLUTE(.);
    . = ALIGN(4);
    _thread_local_start = ABSOLUTE(.);
    *(.tdata)
    *(.tdata.*)
    *(.tbss)
    *(.tbss.*)
    _thread_local_end = ABSOLUTE(.);
    . = ALIGN(4);
  } > default_rodata_seg

  _flash_rodata_align = ALIGNOF(.flash.rodata);

  /*
    This section is a place where we dump all the rodata which aren't used at runtime,
    so as to avoid binary size increase
  */
  .flash.rodata_noload (NOLOAD) :
  {
    /*
      This is a symbol marking the flash.rodata end, this can be used for mmu driver to maintain virtual address
      We don't need to include the noload rodata in this section
    */
    _rodata_reserved_end = ABSOLUTE(.);
    . = ALIGN (4);
    *(.rodata_wlog_debug .rodata_wlog_debug.*)
    *(.rodata_wlog_verbose .rodata_wlog_verbose.*)
  } > default_rodata_seg

  /**
   * This section is required to skip flash rodata sections, because `extern_ram_seg`
   * and `drom0_0_seg` are on the same bus
   */
  .ext_ram.dummy (NOLOAD):
  {
    . = ORIGIN(extern_ram_seg) + (_rodata_reserved_end - _flash_rodata_dummy_start);
    . = ALIGN (0x10000);
  } > extern_ram_seg

  /* This section holds .ext_ram.bss data, and will be put in PSRAM */
  .ext_ram.bss (NOLOAD) :
  {
    _ext_ram_bss_start = ABSOLUTE(.);
    . = ALIGN(4);
    _ext_ram_bss_end = ABSOLUTE(.);
  } > extern_ram_seg

  /**
   * This section holds data that won't be initialised when startup.
   * This section locates in External RAM region.
   */
  .ext_ram_noinit (NOLOAD) :
  {
    _ext_ram_noinit_start = ABSOLUTE(.);

    *(.ext_ram_noinit*)

    . = ALIGN(4);
    _ext_ram_noinit_end = ABSOLUTE(.);
  } > extern_ram_seg

  /* Marks the end of IRAM code segment */
  .iram0.text_end (NOLOAD) :
  {
    /* iram_end_test section exists for use by memprot unit tests only */
    *(.iram_end_test)
    /* ESP32-S3 memprot requires 16B padding for possible CPU prefetch and 256B alignment for PMS split lines */
    . += _esp_memprot_prefetch_pad_size;
    . = ALIGN(_esp_memprot_align_size);
    _iram_text_end = ABSOLUTE(.);
  } > iram0_0_seg

  .iram0.data :
  {
    . = ALIGN(4);
    _iram_data_start = ABSOLUTE(.);

    *(.iram.data .iram.data.*)
    _coredump_iram_start = ABSOLUTE(.);
    *(.iram2.coredump .iram2.coredump.*)
    _coredump_iram_end = ABSOLUTE(.);

    _iram_data_end = ABSOLUTE(.);
  } > iram0_0_seg

  .iram0.bss (NOLOAD) :
  {
    . = ALIGN(4);
    _iram_bss_start = ABSOLUTE(.);

    *(.iram.bss .iram.bss.*)

    _iram_bss_end = ABSOLUTE(.);
    . = ALIGN(4);
    _iram_end = ABSOLUTE(.);
   } > iram0_0_seg

  /* Marks the end of data, bss and possibly rodata  */
  .dram0.heap_start (NOLOAD) :
  {
    . = ALIGN (8);
    /* Lowest possible start address for the heap */
    _heap_low_start = ABSOLUTE(.);
  } > dram0_0_seg

  /** This section will be used by the debugger and disassembler to get more information
    * about raw data present in the code.
    * Indeed, it may be required to add some padding at some points in the code
    * in order to align a branch/jump destination on a particular bound.
    * Padding these instructions will generate null bytes that shall be
    * interpreted as data, and not code by the debugger or disassembler.
    * This section will only be present in the ELF file, not in the final binary
    * For more details, check GCC-212
    */
  .xt.prop 0 :
  {
    KEEP (*(.xt.prop .gnu.linkonce.prop.*))
  }

  .xt.lit 0 :
  {
    KEEP (*(.xt.lit .gnu.linkonce.p.*))
  }
}

ASSERT(((_iram_end - ORIGIN(iram0_0_seg)) <= LENGTH(iram0_0_seg)),
          "IRAM0 segment data does not fit.")

ASSERT(((_heap_low_start - ORIGIN(dram0_0_seg)) <= LENGTH(dram0_0_seg)),
          "DRAM segment data does not fit.")
